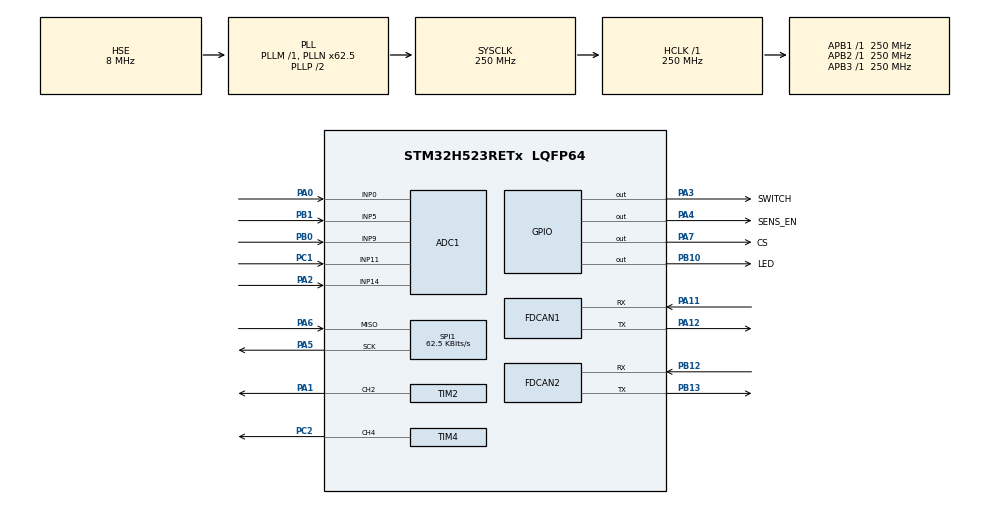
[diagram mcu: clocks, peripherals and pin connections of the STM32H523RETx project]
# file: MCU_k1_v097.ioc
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ADC1.Channel-1\#ChannelRegularConversion=ADC_CHANNEL_0
ADC1.Channel-2\#ChannelRegularConversion=ADC_CHANNEL_5
ADC1.Channel-3\#ChannelRegularConversion=ADC_CHANNEL_9
ADC1.Channel-4\#ChannelRegularConversion=ADC_CHANNEL_11
ADC1.Channel-5\#ChannelRegularConversion=ADC_CHANNEL_14
ADC1.ContinuousConvMode=ENABLE
ADC1.DMAContinuousRequests=ENABLE
ADC1.EOCSelection=ADC_EOC_SEQ_CONV
ADC1.MonitoredBy-1\#ChannelRegularConversion=__NULL
ADC1.MonitoredBy-2\#ChannelRegularConversion=__NULL
ADC1.MonitoredBy-3\#ChannelRegularConversion=__NULL
ADC1.MonitoredBy-4\#ChannelRegularConversion=__NULL
ADC1.MonitoredBy-5\#ChannelRegularConversion=__NULL
ADC1.NbrOfConversion=5
ADC1.NbrOfConversionFlag=1
ADC1.OffsetNumber-1\#ChannelRegularConversion=ADC_OFFSET_NONE
ADC1.OffsetNumber-2\#ChannelRegularConversion=ADC_OFFSET_NONE
ADC1.OffsetNumber-3\#ChannelRegularConversion=ADC_OFFSET_NONE
ADC1.OffsetNumber-4\#ChannelRegularConversion=ADC_OFFSET_NONE
ADC1.OffsetNumber-5\#ChannelRegularConversion=ADC_OFFSET_NONE
ADC1.Rank-1\#ChannelRegularConversion=1
ADC1.Rank-2\#ChannelRegularConversion=2
ADC1.Rank-3\#ChannelRegularConversion=3
ADC1.Rank-4\#ChannelRegularConversion=4
ADC1.Rank-5\#ChannelRegularConversion=5
ADC1.SamplingTime-1\#ChannelRegularConversion=ADC_SAMPLETIME_640CYCLES_5
ADC1.SamplingTime-2\#ChannelRegularConversion=ADC_SAMPLETIME_640CYCLES_5
ADC1.SamplingTime-3\#ChannelRegularConversion=ADC_SAMPLETIME_640CYCLES_5
ADC1.SamplingTime-4\#ChannelRegularConversion=ADC_SAMPLETIME_640CYCLES_5
ADC1.SamplingTime-5\#ChannelRegularConversion=ADC_SAMPLETIME_640CYCLES_5
ADC1.master=1
BOOTPATH.BootPathName=LEGACY
BOOTPATH.UserSelectedBootPath=LEGACY
CORTEX_M33_NS.userName=CORTEX_M33
DTS.Divider=10
DTS.RefClock=DTS_REFCLKSEL_PCLK
DTS.SamplingTime=DTS_SMP_TIME_15_CYCLE
FDCAN1.AutoRetransmission=ENABLE
FDCAN1.CalculateBaudRateNominal=250000
FDCAN1.CalculateTimeBitNominal=4000
FDCAN1.CalculateTimeQuantumNominal=250.0
FDCAN1.DataTimeSeg1=21
FDCAN1.ExtFiltersNbr=1
FDCAN1.NominalPrescaler=2
FDCAN1.NominalSyncJumpWidth=3
FDCAN1.NominalTimeSeg1=12
FDCAN1.NominalTimeSeg2=3
FDCAN1.StdFiltersNbr=1
FDCAN2.AutoRetransmission=ENABLE
FDCAN2.CalculateBaudRateNominal=250000
FDCAN2.CalculateTimeBitNominal=4000
FDCAN2.CalculateTimeQuantumNominal=250.0
FDCAN2.DataTimeSeg1=21
FDCAN2.ExtFiltersNbr=1
FDCAN2.NominalPrescaler=2
FDCAN2.NominalSyncJumpWidth=3
FDCAN2.NominalTimeSeg1=12
FDCAN2.NominalTimeSeg2=3
FDCAN2.StdFiltersNbr=1
GPDMA1.CIRCULARMODE_GPDMACH0=ENABLE
GPDMA1.DESTDATAWIDTH_GPDMACH0=DMA_DEST_DATAWIDTH_HALFWORD
GPDMA1.DESTINC_GPDMACH0=DMA_DINC_INCREMENTED
GPDMA1.IPHANDLE_GPDMACH0-SIMPLEREQUEST_GPDMACH0=__NULL
GPDMA1.REQUEST_GPDMACH0=GPDMA1_REQUEST_ADC1
GPDMA1.SRCDATAWIDTH_GPDMACH0=DMA_SRC_DATAWIDTH_HALFWORD
Mcu.Family=STM32H5
Mcu.Name=STM32H523RETx
Mcu.Package=LQFP64
NVIC.ADC1_IRQn=true\:10\:0\:true\:false\:true\:true\:true\:true
NVIC.DTS_IRQn=true\:12\:0\:true\:false\:true\:true\:true\:true
NVIC.FDCAN1_IT0_IRQn=true\:1\:0\:true\:false\:true\:true\:true\:true
NVIC.FDCAN2_IT0_IRQn=true\:2\:0\:true\:false\:true\:true\:true\:true
NVIC.GPDMA1_Channel0_IRQn=true\:9\:0\:true\:false\:true\:false\:true\:true
NVIC.PriorityGroup=NVIC_PRIORITYGROUP_4
PA0.Signal=ADCx_INP0
PA1.Signal=S_TIM2_CH2
PA11.GPIO_Speed=GPIO_SPEED_FREQ_VERY_HIGH
PA11.Mode=FDCAN_Activate
PA11.Signal=FDCAN1_RX
PA12.GPIO_Speed=GPIO_SPEED_FREQ_VERY_HIGH
PA12.Mode=FDCAN_Activate
PA12.Signal=FDCAN1_TX
PA2.Signal=ADCx_INP14
PA3.GPIO_Label=SWITCH
PA3.Signal=GPIO_Output
PA4.GPIO_Label=SENS_EN
PA4.Signal=GPIO_Output
PA5.Mode=RX_Only_Simplex_Unidirect_Master
PA5.Signal=SPI1_SCK
PA6.Mode=RX_Only_Simplex_Unidirect_Master
PA6.Signal=SPI1_MISO
PA7.GPIO_Label=CS
PA7.Signal=GPIO_Output
PB0.Signal=ADCx_INP9
PB1.Signal=ADCx_INP5
PB10.GPIO_Label=LED
PB10.Signal=GPIO_Output
PB12.GPIO_Speed=GPIO_SPEED_FREQ_VERY_HIGH
PB12.Mode=FDCAN_Activate
PB12.Signal=FDCAN2_RX
PB13.GPIO_Speed=GPIO_SPEED_FREQ_VERY_HIGH
PB13.Mode=FDCAN_Activate
PB13.Signal=FDCAN2_TX
PC1.Signal=ADCx_INP11
PC2.Signal=S_TIM4_CH4
PH0-OSC_IN(PH0).Mode=HSE-External-Oscillator
PH0-OSC_IN(PH0).Signal=RCC_OSC_IN
PH1-OSC_OUT(PH1).Mode=HSE-External-Oscillator
PH1-OSC_OUT(PH1).Signal=RCC_OSC_OUT
ProjectManager.HeapSize=0x200
ProjectManager.StackSize=0x400
ProjectManager.TargetToolchain=STM32CubeIDE
RCC.ADCFreq_Value=250000000
RCC.AHBFreq_Value=250000000
RCC.APB1Freq_Value=250000000
RCC.APB1TimFreq_Value=250000000
RCC.APB2Freq_Value=250000000
RCC.APB2TimFreq_Value=250000000
RCC.APB3Freq_Value=250000000
RCC.CSI_VALUE=4000000
RCC.CortexFreq_Value=250000000
RCC.EPOD_VALUE=8000000
RCC.FDCANClockSelection=RCC_FDCANCLKSOURCE_HSE
RCC.HCLKFreq_Value=250000000
RCC.HSE_VALUE=8000000
RCC.HSI48_VALUE=48000000
RCC.HSI_VALUE=64000000
RCC.LSE_VALUE=32768
RCC.LSIRC_VALUE=32000
RCC.PLL1Q=125
RCC.PLL2FRACN=0
RCC.PLL2Source=RCC_PLL2_SOURCE_HSE
RCC.PLL3FRACN=0
RCC.PLL3Source=RCC_PLL3_SOURCE_HSE
RCC.PLLFRACN=4096
RCC.PLLN=62
RCC.PLLSourceVirtual=RCC_PLL1_SOURCE_HSE
RCC.SYSCLKFreq_VALUE=250000000
RCC.SYSCLKSource=RCC_SYSCLKSOURCE_PLLCLK
RCC.USBFreq_Value=48000000
RCC.VCOOutputFreq_Value=500000000
SH.ADCx_INP0.0=ADC1_INP0,IN0-Single-Ended
SH.ADCx_INP11.0=ADC1_INP11,IN11-Single-Ended
SH.ADCx_INP14.0=ADC1_INP14,IN14-Single-Ended
SH.ADCx_INP5.0=ADC1_INP5,IN5-Single-Ended
SH.ADCx_INP9.0=ADC1_INP9,IN9-Single-Ended
SH.S_TIM2_CH2.0=TIM2_CH2,PWM Generation2 CH2
SH.S_TIM4_CH4.0=TIM4_CH4,PWM Generation4 CH4
SPI1.BaudRatePrescaler=SPI_BAUDRATEPRESCALER_64
SPI1.CalculateBaudRate=62.5 KBits/s
SPI1.DataSize=SPI_DATASIZE_8BIT
SPI1.Direction=SPI_DIRECTION_2LINES_RXONLY
SPI1.Mode=SPI_MODE_MASTER
SPI1.VirtualType=VM_MASTER
TIM2.Channel-PWM\ Generation2\ CH2=TIM_CHANNEL_2
TIM2.PeriodNoDither=99
TIM2.Prescaler=31
TIM4.Channel-PWM\ Generation4\ CH4=TIM_CHANNEL_4
TIM4.PeriodNoDither=99
TIM4.Prescaler=31
VP_BOOTPATH_VS_BOOTPATH.Mode=BP_Activate
VP_CORTEX_M33_NS_VS_Hclk.Mode=Hclk_Mode
VP_DTS_VS-DTS.Mode=DTS
VP_GPDMA1_VS_GPDMACH0.Mode=SIMPLEREQUEST_GPDMACH0
VP_MEMORYMAP_VS_MEMORYMAP.Mode=CurAppReg
VP_PWR_VS_LPOM.Mode=PowerOptimisation
VP_PWR_VS_SECSignals.Mode=Security/Privilege
VP_TIM2_VS_ClockSourceINT.Mode=Internal
VP_TIM4_VS_ClockSourceINT.Mode=Internal
board=custom

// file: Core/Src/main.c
/* USER CODE BEGIN Header */
/**
  ******************************************************************************
  * @file           : main.c
  * @brief          : Main program body
  ******************************************************************************
  * @attention
  *
  * Copyright (c) 2026 STMicroelectronics.
  * All rights reserved.
  *
  * This software is licensed under terms that can be found in the LICENSE file
  * in the root directory of this software component.
  * If no LICENSE file comes with this software, it is provided AS-IS.
  *
  ******************************************************************************
  */
/* USER CODE END Header */
#include "main.h"

/* USER CODE BEGIN Includes */
#include "backend.h"
#include "app.h"

/* USER CODE END Includes */

ADC_HandleTypeDef hadc1;
DMA_NodeTypeDef Node_GPDMA1_Channel0;
DMA_QListTypeDef List_GPDMA1_Channel0;
DMA_HandleTypeDef handle_GPDMA1_Channel0;

DTS_HandleTypeDef hdts;

FDCAN_HandleTypeDef hfdcan1;
FDCAN_HandleTypeDef hfdcan2;

SPI_HandleTypeDef hspi1;

TIM_HandleTypeDef htim2;
TIM_HandleTypeDef htim4;

void SystemClock_Config(void);
static void MX_GPIO_Init(void);
static void MX_GPDMA1_Init(void);
static void MX_ADC1_Init(void);
static void MX_FDCAN1_Init(void);
static void MX_FDCAN2_Init(void);
static void MX_TIM4_Init(void);
static void MX_SPI1_Init(void);
static void MX_TIM2_Init(void);
static void MX_DTS_Init(void);

int main(void)
{

  /* MCU Configuration--------------------------------------------------------*/

  /* Reset of all peripherals, Initializes the Flash interface and the Systick. */
  HAL_Init();

  /* Configure the system clock */
  SystemClock_Config();

  /* Initialize all configured peripherals */
  MX_GPIO_Init();
  MX_GPDMA1_Init();
  MX_ADC1_Init();
  MX_FDCAN1_Init();
  MX_FDCAN2_Init();
  MX_TIM4_Init();
  MX_SPI1_Init();
  MX_TIM2_Init();
  MX_DTS_Init();
  /* USER CODE BEGIN 2 */
  if (HAL_DTS_Start(&hdts) != HAL_OK)
  {
    Error_Handler();
  }
  FDCAN_StartAll();
  (void)HAL_ADC_Start_DMA(&hadc1, (uint32_t *)MCU_K1_ADC_VAL, MCU_K1_NUM_ADC_CHANNEL);
  App_Init();

  /* USER CODE END 2 */

  /* Infinite loop */
  while (1)
  {

    /* USER CODE BEGIN 3 */
    static uint32_t last_tick = 0;
    uint32_t now = HAL_GetTick();
    if (now != last_tick) {
      last_tick = now;
      App_Timer1ms();
    }
    App_CanProcess();
    App_CanTxProcess();
  }
  /* USER CODE END 3 */
}

void SystemClock_Config(void)
{
  RCC_OscInitTypeDef RCC_OscInitStruct = {0};
  RCC_ClkInitTypeDef RCC_ClkInitStruct = {0};

  /** Configure the main internal regulator output voltage
  */
  __HAL_PWR_VOLTAGESCALING_CONFIG(PWR_REGULATOR_VOLTAGE_SCALE0);

  while(!__HAL_PWR_GET_FLAG(PWR_FLAG_VOSRDY)) {}

  /** Initializes the RCC Oscillators according to the specified parameters
  * in the RCC_OscInitTypeDef structure.
  */
  RCC_OscInitStruct.OscillatorType = RCC_OSCILLATORTYPE_HSE;
  RCC_OscInitStruct.HSEState = RCC_HSE_ON;
  RCC_OscInitStruct.PLL.PLLState = RCC_PLL_ON;
  RCC_OscInitStruct.PLL.PLLSource = RCC_PLL1_SOURCE_HSE;
  RCC_OscInitStruct.PLL.PLLM = 1;
  RCC_OscInitStruct.PLL.PLLN = 62;
  RCC_OscInitStruct.PLL.PLLP = 2;
  RCC_OscInitStruct.PLL.PLLQ = 125;
  RCC_OscInitStruct.PLL.PLLR = 2;
  RCC_OscInitStruct.PLL.PLLRGE = RCC_PLL1_VCIRANGE_3;
  RCC_OscInitStruct.PLL.PLLVCOSEL = RCC_PLL1_VCORANGE_WIDE;
  RCC_OscInitStruct.PLL.PLLFRACN = 4096;
  if (HAL_RCC_OscConfig(&RCC_OscInitStruct) != HAL_OK)
  {
    Error_Handler();
  }

  /** Initializes the CPU, AHB and APB buses clocks
  */
  RCC_ClkInitStruct.ClockType = RCC_CLOCKTYPE_HCLK|RCC_CLOCKTYPE_SYSCLK
                              |RCC_CLOCKTYPE_PCLK1|RCC_CLOCKTYPE_PCLK2
                              |RCC_CLOCKTYPE_PCLK3;
  RCC_ClkInitStruct.SYSCLKSource = RCC_SYSCLKSOURCE_PLLCLK;
  RCC_ClkInitStruct.AHBCLKDivider = RCC_SYSCLK_DIV1;
  RCC_ClkInitStruct.APB1CLKDivider = RCC_HCLK_DIV1;
  RCC_ClkInitStruct.APB2CLKDivider = RCC_HCLK_DIV1;
  RCC_ClkInitStruct.APB3CLKDivider = RCC_HCLK_DIV1;

  if (HAL_RCC_ClockConfig(&RCC_ClkInitStruct, FLASH_LATENCY_5) != HAL_OK)
  {
    Error_Handler();
  }

  /** Configure the programming delay
  */
  __HAL_FLASH_SET_PROGRAM_DELAY(FLASH_PROGRAMMING_DELAY_2);
}

static void MX_ADC1_Init(void)
{

  ADC_ChannelConfTypeDef sConfig = {0};

  /** Common config
  */
  hadc1.Instance = ADC1;
  hadc1.Init.ClockPrescaler = ADC_CLOCK_ASYNC_DIV4;
  hadc1.Init.Resolution = ADC_RESOLUTION_12B;
  hadc1.Init.DataAlign = ADC_DATAALIGN_RIGHT;
  hadc1.Init.ScanConvMode = ADC_SCAN_ENABLE;
  hadc1.Init.EOCSelection = ADC_EOC_SEQ_CONV;
  hadc1.Init.LowPowerAutoWait = DISABLE;
  hadc1.Init.ContinuousConvMode = ENABLE;
  hadc1.Init.NbrOfConversion = 5;
  hadc1.Init.DiscontinuousConvMode = DISABLE;
  hadc1.Init.ExternalTrigConv = ADC_SOFTWARE_START;
  hadc1.Init.ExternalTrigConvEdge = ADC_EXTERNALTRIGCONVEDGE_NONE;
  hadc1.Init.DMAContinuousRequests = ENABLE;
  hadc1.Init.SamplingMode = ADC_SAMPLING_MODE_NORMAL;
  hadc1.Init.Overrun = ADC_OVR_DATA_PRESERVED;
  hadc1.Init.OversamplingMode = DISABLE;
  if (HAL_ADC_Init(&hadc1) != HAL_OK)
  {
    Error_Handler();
  }

  /** Configure Regular Channel
  */
  sConfig.Channel = ADC_CHANNEL_0;
  sConfig.Rank = ADC_REGULAR_RANK_1;
  sConfig.SamplingTime = ADC_SAMPLETIME_640CYCLES_5;
  sConfig.SingleDiff = ADC_SINGLE_ENDED;
  sConfig.OffsetNumber = ADC_OFFSET_NONE;
  sConfig.Offset = 0;
  if (HAL_ADC_ConfigChannel(&hadc1, &sConfig) != HAL_OK)
  {
    Error_Handler();
  }

  /** Configure Regular Channel
  */
  sConfig.Channel = ADC_CHANNEL_5;
  sConfig.Rank = ADC_REGULAR_RANK_2;
  if (HAL_ADC_ConfigChannel(&hadc1, &sConfig) != HAL_OK)
  {
    Error_Handler();
  }

  /** Configure Regular Channel
  */
  sConfig.Channel = ADC_CHANNEL_9;
  sConfig.Rank = ADC_REGULAR_RANK_3;
  if (HAL_ADC_ConfigChannel(&hadc1, &sConfig) != HAL_OK)
  {
    Error_Handler();
  }

  /** Configure Regular Channel
  */
  sConfig.Channel = ADC_CHANNEL_11;
  sConfig.Rank = ADC_REGULAR_RANK_4;
  if (HAL_ADC_ConfigChannel(&hadc1, &sConfig) != HAL_OK)
  {
    Error_Handler();
  }

  /** Configure Regular Channel
  */
  sConfig.Channel = ADC_CHANNEL_14;
  sConfig.Rank = ADC_REGULAR_RANK_5;
  if (HAL_ADC_ConfigChannel(&hadc1, &sConfig) != HAL_OK)
  {
    Error_Handler();
  }

}

static void MX_DTS_Init(void)
{

  hdts.Instance = DTS;
  hdts.Init.QuickMeasure = DTS_QUICKMEAS_DISABLE;
  hdts.Init.RefClock = DTS_REFCLKSEL_PCLK;
  hdts.Init.TriggerInput = DTS_TRIGGER_HW_NONE;
  hdts.Init.SamplingTime = DTS_SMP_TIME_15_CYCLE;
  hdts.Init.Divider = 10;
  hdts.Init.HighThreshold = 0x0;
  hdts.Init.LowThreshold = 0x0;
  if (HAL_DTS_Init(&hdts) != HAL_OK)
  {
    Error_Handler();
  }

}

static void MX_FDCAN1_Init(void)
{

  hfdcan1.Instance = FDCAN1;
  hfdcan1.Init.ClockDivider = FDCAN_CLOCK_DIV1;
  hfdcan1.Init.FrameFormat = FDCAN_FRAME_CLASSIC;
  hfdcan1.Init.Mode = FDCAN_MODE_NORMAL;
  hfdcan1.Init.AutoRetransmission = ENABLE;
  hfdcan1.Init.TransmitPause = DISABLE;
  hfdcan1.Init.ProtocolException = DISABLE;
  hfdcan1.Init.NominalPrescaler = 2;
  hfdcan1.Init.NominalSyncJumpWidth = 3;
  hfdcan1.Init.NominalTimeSeg1 = 12;
  hfdcan1.Init.NominalTimeSeg2 = 3;
  hfdcan1.Init.DataPrescaler = 1;
  hfdcan1.Init.DataSyncJumpWidth = 1;
  hfdcan1.Init.DataTimeSeg1 = 21;
  hfdcan1.Init.DataTimeSeg2 = 1;
  hfdcan1.Init.StdFiltersNbr = 1;
  hfdcan1.Init.ExtFiltersNbr = 1;
  hfdcan1.Init.TxFifoQueueMode = FDCAN_TX_FIFO_OPERATION;
  if (HAL_FDCAN_Init(&hfdcan1) != HAL_OK)
  {
    Error_Handler();
  }

}

static void MX_FDCAN2_Init(void)
{

  hfdcan2.Instance = FDCAN2;
  hfdcan2.Init.ClockDivider = FDCAN_CLOCK_DIV1;
  hfdcan2.Init.FrameFormat = FDCAN_FRAME_CLASSIC;
  hfdcan2.Init.Mode = FDCAN_MODE_NORMAL;
  hfdcan2.Init.AutoRetransmission = ENABLE;
  hfdcan2.Init.TransmitPause = DISABLE;
  hfdcan2.Init.ProtocolException = DISABLE;
  hfdcan2.Init.NominalPrescaler = 2;
  hfdcan2.Init.NominalSyncJumpWidth = 3;
  hfdcan2.Init.NominalTimeSeg1 = 12;
  hfdcan2.Init.NominalTimeSeg2 = 3;
  hfdcan2.Init.DataPrescaler = 1;
  hfdcan2.Init.DataSyncJumpWidth = 1;
  hfdcan2.Init.DataTimeSeg1 = 21;
  hfdcan2.Init.DataTimeSeg2 = 1;
  hfdcan2.Init.StdFiltersNbr = 1;
  hfdcan2.Init.ExtFiltersNbr = 1;
  hfdcan2.Init.TxFifoQueueMode = FDCAN_TX_FIFO_OPERATION;
  if (HAL_FDCAN_Init(&hfdcan2) != HAL_OK)
  {
    Error_Handler();
  }

}

static void MX_GPDMA1_Init(void)
{

  /* Peripheral clock enable */
  __HAL_RCC_GPDMA1_CLK_ENABLE();

  /* GPDMA1 interrupt Init */
    HAL_NVIC_SetPriority(GPDMA1_Channel0_IRQn, 9, 0);
    HAL_NVIC_EnableIRQ(GPDMA1_Channel0_IRQn);

}

static void MX_SPI1_Init(void)
{

  /* SPI1 parameter configuration*/
  hspi1.Instance = SPI1;
  hspi1.Init.Mode = SPI_MODE_MASTER;
  hspi1.Init.Direction = SPI_DIRECTION_2LINES_RXONLY;
  hspi1.Init.DataSize = SPI_DATASIZE_8BIT;
  hspi1.Init.CLKPolarity = SPI_POLARITY_LOW;
  hspi1.Init.CLKPhase = SPI_PHASE_1EDGE;
  hspi1.Init.NSS = SPI_NSS_SOFT;
  hspi1.Init.BaudRatePrescaler = SPI_BAUDRATEPRESCALER_64;
  hspi1.Init.FirstBit = SPI_FIRSTBIT_MSB;
  hspi1.Init.TIMode = SPI_TIMODE_DISABLE;
  hspi1.Init.CRCCalculation = SPI_CRCCALCULATION_DISABLE;
  hspi1.Init.CRCPolynomial = 0x7;
  hspi1.Init.NSSPMode = SPI_NSS_PULSE_ENABLE;
  hspi1.Init.NSSPolarity = SPI_NSS_POLARITY_LOW;
  hspi1.Init.FifoThreshold = SPI_FIFO_THRESHOLD_01DATA;
  hspi1.Init.MasterSSIdleness = SPI_MASTER_SS_IDLENESS_00CYCLE;
  hspi1.Init.MasterInterDataIdleness = SPI_MASTER_INTERDATA_IDLENESS_00CYCLE;
  hspi1.Init.MasterReceiverAutoSusp = SPI_MASTER_RX_AUTOSUSP_DISABLE;
  hspi1.Init.MasterKeepIOState = SPI_MASTER_KEEP_IO_STATE_DISABLE;
  hspi1.Init.IOSwap = SPI_IO_SWAP_DISABLE;
  hspi1.Init.ReadyMasterManagement = SPI_RDY_MASTER_MANAGEMENT_INTERNALLY;
  hspi1.Init.ReadyPolarity = SPI_RDY_POLARITY_HIGH;
  if (HAL_SPI_Init(&hspi1) != HAL_OK)
  {
    Error_Handler();
  }

}

static void MX_TIM2_Init(void)
{

  TIM_ClockConfigTypeDef sClockSourceConfig = {0};
  TIM_MasterConfigTypeDef sMasterConfig = {0};
  TIM_OC_InitTypeDef sConfigOC = {0};

  htim2.Instance = TIM2;
  htim2.Init.Prescaler = 31;
  htim2.Init.CounterMode = TIM_COUNTERMODE_UP;
  htim2.Init.Period = 99;
  htim2.Init.ClockDivision = TIM_CLOCKDIVISION_DIV1;
  htim2.Init.AutoReloadPreload = TIM_AUTORELOAD_PRELOAD_DISABLE;
  if (HAL_TIM_Base_Init(&htim2) != HAL_OK)
  {
    Error_Handler();
  }
  sClockSourceConfig.ClockSource = TIM_CLOCKSOURCE_INTERNAL;
  if (HAL_TIM_ConfigClockSource(&htim2, &sClockSourceConfig) != HAL_OK)
  {
    Error_Handler();
  }
  if (HAL_TIM_PWM_Init(&htim2) != HAL_OK)
  {
    Error_Handler();
  }
  sMasterConfig.MasterOutputTrigger = TIM_TRGO_RESET;
  sMasterConfig.MasterSlaveMode = TIM_MASTERSLAVEMODE_DISABLE;
  if (HAL_TIMEx_MasterConfigSynchronization(&htim2, &sMasterConfig) != HAL_OK)
  {
    Error_Handler();
  }
  sConfigOC.OCMode = TIM_OCMODE_PWM1;
  sConfigOC.Pulse = 0;
  sConfigOC.OCPolarity = TIM_OCPOLARITY_HIGH;
  sConfigOC.OCFastMode = TIM_OCFAST_DISABLE;
  if (HAL_TIM_PWM_ConfigChannel(&htim2, &sConfigOC, TIM_CHANNEL_2) != HAL_OK)
  {
    Error_Handler();
  }
  HAL_TIM_MspPostInit(&htim2);

}

static void MX_TIM4_Init(void)
{

  TIM_ClockConfigTypeDef sClockSourceConfig = {0};
  TIM_MasterConfigTypeDef sMasterConfig = {0};
  TIM_OC_InitTypeDef sConfigOC = {0};

  htim4.Instance = TIM4;
  htim4.Init.Prescaler = 31;
  htim4.Init.CounterMode = TIM_COUNTERMODE_UP;
  htim4.Init.Period = 99;
  htim4.Init.ClockDivision = TIM_CLOCKDIVISION_DIV1;
  htim4.Init.AutoReloadPreload = TIM_AUTORELOAD_PRELOAD_DISABLE;
  if (HAL_TIM_Base_Init(&htim4) != HAL_OK)
  {
    Error_Handler();
  }
  sClockSourceConfig.ClockSource = TIM_CLOCKSOURCE_INTERNAL;
  if (HAL_TIM_ConfigClockSource(&htim4, &sClockSourceConfig) != HAL_OK)
  {
    Error_Handler();
  }
  if (HAL_TIM_PWM_Init(&htim4) != HAL_OK)
  {
    Error_Handler();
  }
  sMasterConfig.MasterOutputTrigger = TIM_TRGO_RESET;
  sMasterConfig.MasterSlaveMode = TIM_MASTERSLAVEMODE_DISABLE;
  if (HAL_TIMEx_MasterConfigSynchronization(&htim4, &sMasterConfig) != HAL_OK)
  {
    Error_Handler();
  }
  sConfigOC.OCMode = TIM_OCMODE_PWM1;
  sConfigOC.Pulse = 0;
  sConfigOC.OCPolarity = TIM_OCPOLARITY_HIGH;
  sConfigOC.OCFastMode = TIM_OCFAST_DISABLE;
  if (HAL_TIM_PWM_ConfigChannel(&htim4, &sConfigOC, TIM_CHANNEL_4) != HAL_OK)
  {
    Error_Handler();
  }
  HAL_TIM_MspPostInit(&htim4);

}

static void MX_GPIO_Init(void)
{
  GPIO_InitTypeDef GPIO_InitStruct = {0};

  /* GPIO Ports Clock Enable */
  __HAL_RCC_GPIOH_CLK_ENABLE();
  __HAL_RCC_GPIOC_CLK_ENABLE();
  __HAL_RCC_GPIOA_CLK_ENABLE();
  __HAL_RCC_GPIOB_CLK_ENABLE();

  /*Configure GPIO pin Output Level */
  HAL_GPIO_WritePin(GPIOA, SWITCH_Pin|SENS_EN_Pin|CS_Pin, GPIO_PIN_RESET);

  /*Configure GPIO pin Output Level */
  HAL_GPIO_WritePin(LED_GPIO_Port, LED_Pin, GPIO_PIN_RESET);

  /*Configure GPIO pins : SWITCH_Pin SENS_EN_Pin CS_Pin */
  GPIO_InitStruct.Pin = SWITCH_Pin|SENS_EN_Pin|CS_Pin;
  GPIO_InitStruct.Mode = GPIO_MODE_OUTPUT_PP;
  GPIO_InitStruct.Pull = GPIO_NOPULL;
  GPIO_InitStruct.Speed = GPIO_SPEED_FREQ_LOW;
  HAL_GPIO_Init(GPIOA, &GPIO_InitStruct);

  /*Configure GPIO pin : LED_Pin */
  GPIO_InitStruct.Pin = LED_Pin;
  GPIO_InitStruct.Mode = GPIO_MODE_OUTPUT_PP;
  GPIO_InitStruct.Pull = GPIO_NOPULL;
  GPIO_InitStruct.Speed = GPIO_SPEED_FREQ_LOW;
  HAL_GPIO_Init(LED_GPIO_Port, &GPIO_InitStruct);

}

void Error_Handler(void)
{
  __disable_irq();
  while (1)
  {
  }
}
